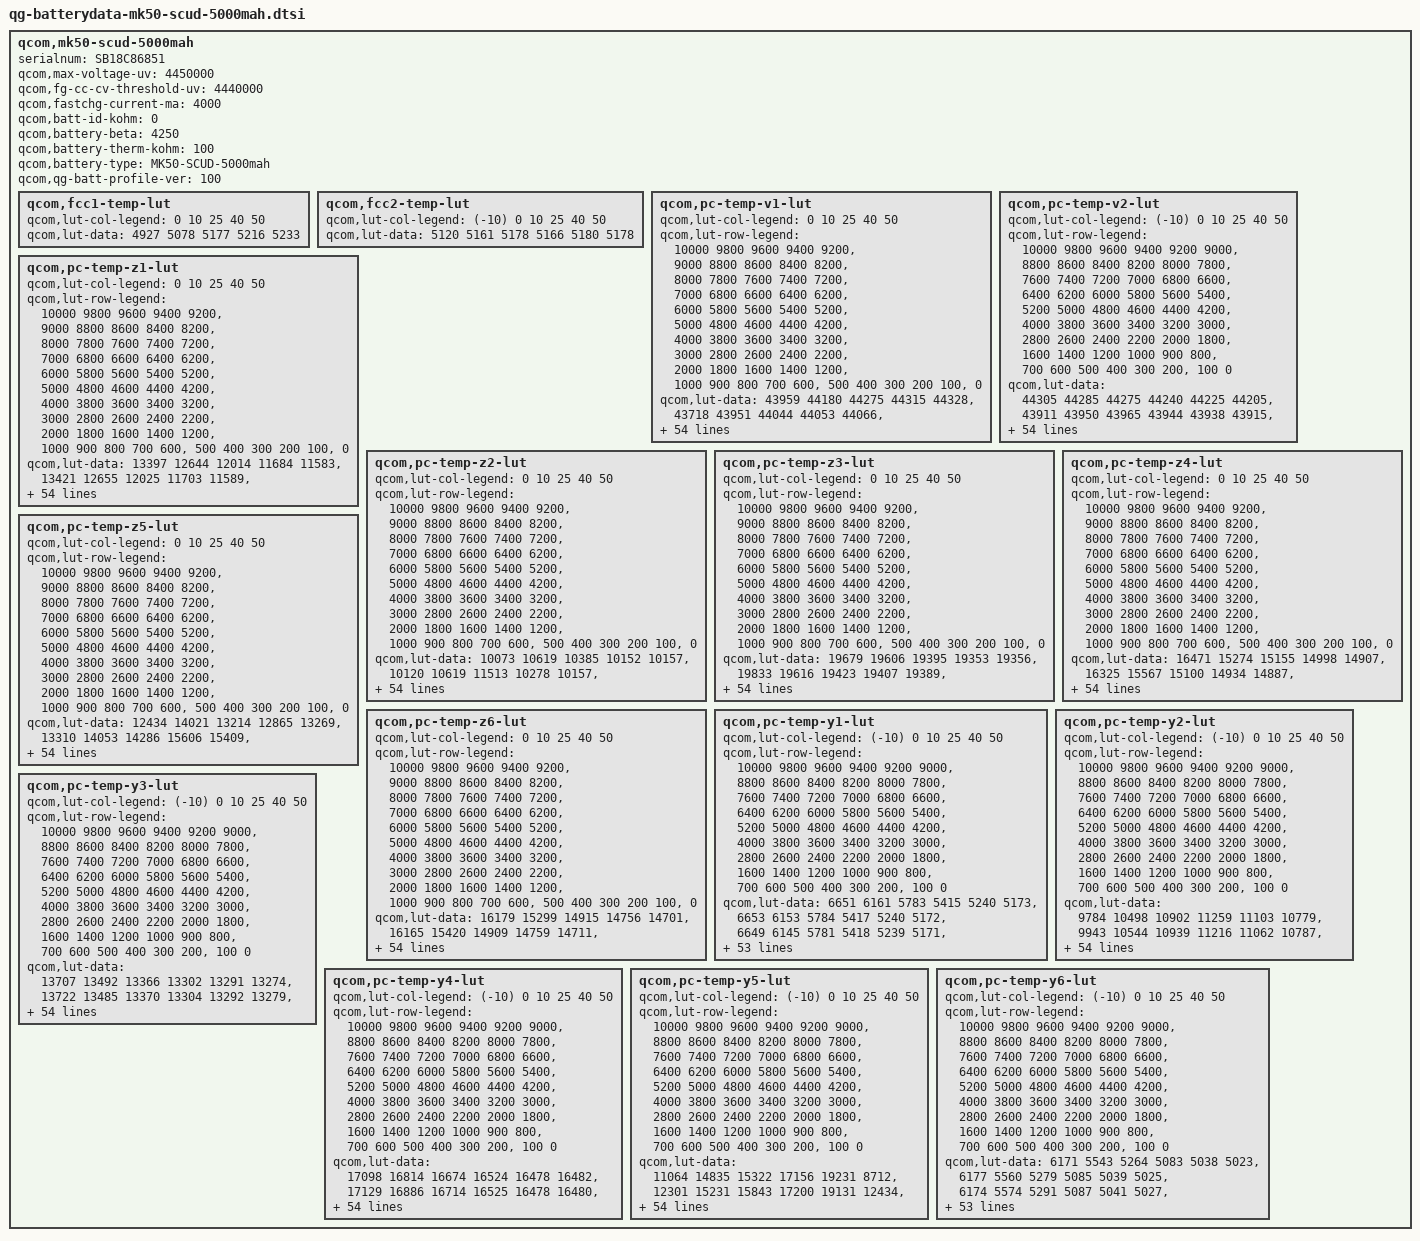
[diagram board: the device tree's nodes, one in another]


qcom,mk50-scud-5000mah {
    serialnum = "SB18C86851";

    qcom,max-voltage-uv = <4450000>;
    qcom,fg-cc-cv-threshold-uv = <4440000>;
    qcom,fastchg-current-ma = <4000>;
    qcom,batt-id-kohm = <0>;
    qcom,battery-beta = <4250>;
    qcom,battery-therm-kohm = <100>;
    qcom,battery-type = "MK50-SCUD-5000mah";
    qcom,qg-batt-profile-ver = <100>;

	qcom,fcc1-temp-lut {
		qcom,lut-col-legend = <0 10 25 40 50>;
		qcom,lut-data = <4927 5078 5177 5216 5233>;
	};

	qcom,fcc2-temp-lut {
		qcom,lut-col-legend = <(-10) 0 10 25 40 50>;
		qcom,lut-data = <5120 5161 5178 5166 5180 5178>;
	};

	qcom,pc-temp-v1-lut {
		qcom,lut-col-legend = <0 10 25 40 50>;
		qcom,lut-row-legend = <10000 9800 9600 9400 9200>,
			<9000 8800 8600 8400 8200>,
			<8000 7800 7600 7400 7200>,
			<7000 6800 6600 6400 6200>,
			<6000 5800 5600 5400 5200>,
			<5000 4800 4600 4400 4200>,
			<4000 3800 3600 3400 3200>,
			<3000 2800 2600 2400 2200>,
			<2000 1800 1600 1400 1200>,
			<1000 900 800 700 600>,
			<500 400 300 200 100>,
			<0>;
		qcom,lut-data = <43959 44180 44275 44315 44328>,
			<43718 43951 44044 44053 44066>,
			<43478 43724 43830 43832 43841>,
			<43240 43494 43605 43627 43632>,
			<43002 43258 43375 43414 43417>,
			<42763 43016 43141 43187 43194>,
			<42523 42773 42901 42946 42961>,
			<42284 42531 42658 42703 42723>,
			<42051 42289 42412 42461 42483>,
			<41822 42050 42167 42219 42241>,
			<41596 41815 41927 41979 42003>,
			<41377 41584 41691 41741 41765>,
			<41162 41360 41462 41509 41531>,
			<40955 41143 41238 41278 41301>,
			<40749 40933 41020 41055 41078>,
			<40539 40727 40810 40843 40861>,
			<40327 40520 40603 40639 40650>,
			<40131 40314 40400 40439 40448>,
			<39956 40120 40203 40246 40254>,
			<39796 39948 40022 40061 40068>,
			<39644 39786 39865 39893 39903>,
			<39502 39620 39688 39717 39734>,
			<39363 39449 39426 39472 39503>,
			<39220 39257 39133 39173 39207>,
			<39075 39010 38942 38968 38993>,
			<38929 38772 38810 38843 38865>,
			<38775 38644 38704 38739 38761>,
			<38642 38565 38616 38641 38660>,
			<38545 38499 38540 38551 38567>,
			<38467 38439 38466 38465 38477>,
			<38407 38386 38398 38386 38392>,
			<38360 38337 38334 38312 38312>,
			<38321 38292 38276 38245 38234>,
			<38285 38249 38220 38181 38160>,
			<38254 38210 38167 38116 38087>,
			<38222 38171 38117 38051 38017>,
			<38190 38134 38069 37991 37951>,
			<38154 38095 38024 37941 37895>,
			<38099 38041 37968 37880 37829>,
			<38018 37956 37881 37789 37729>,
			<37919 37850 37771 37674 37605>,
			<37790 37729 37653 37556 37482>,
			<37648 37588 37518 37428 37355>,
			<37506 37420 37355 37274 37204>,
			<37346 37262 37196 37124 37060>,
			<37223 37158 37088 37027 36971>,
			<37178 37129 37057 36992 36938>,
			<37142 37097 37038 36972 36914>,
			<37109 37070 37016 36952 36894>,
			<37068 37032 36977 36908 36842>,
			<36912 36861 36790 36696 36610>,
			<36482 36432 36371 36263 36172>,
			<35900 35841 35793 35684 35592>,
			<35093 35023 35004 34897 34803>,
			<33747 33682 33778 33686 33586>,
			<30000 30000 30000 30000 30000>;
	};

	qcom,pc-temp-v2-lut {
		qcom,lut-col-legend = <(-10) 0 10 25 40 50>;
		qcom,lut-row-legend = <10000 9800 9600 9400 9200 9000>,
			<8800 8600 8400 8200 8000 7800>,
			<7600 7400 7200 7000 6800 6600>,
			<6400 6200 6000 5800 5600 5400>,
			<5200 5000 4800 4600 4400 4200>,
			<4000 3800 3600 3400 3200 3000>,
			<2800 2600 2400 2200 2000 1800>,
			<1600 1400 1200 1000 900 800>,
			<700 600 500 400 300 200>,
			<100 0>;
		qcom,lut-data = <44305 44285 44275 44240 44225 44205>,
			<43911 43950 43965 43944 43938 43915>,
			<43561 43644 43679 43670 43672 43648>,
			<43264 43373 43421 43421 43427 43406>,
			<43013 43132 43189 43197 43203 43187>,
			<42761 42891 42954 42968 42975 42962>,
			<42484 42643 42708 42728 42737 42722>,
			<42214 42395 42460 42485 42495 42479>,
			<41988 42145 42212 42242 42254 42240>,
			<41790 41894 41963 42000 42011 42001>,
			<41570 41636 41723 41762 41773 41766>,
			<41294 41352 41492 41526 41537 41530>,
			<41036 41102 41267 41297 41307 41299>,
			<40877 40933 41051 41079 41081 41074>,
			<40751 40792 40838 40866 40861 40853>,
			<40548 40615 40629 40652 40647 40639>,
			<40156 40398 40424 40435 40439 40431>,
			<39761 40150 40212 40229 40239 40231>,
			<39487 39840 39984 40048 40053 40046>,
			<39256 39524 39748 39869 39870 39865>,
			<39050 39300 39517 39659 39680 39680>,
			<38864 39125 39287 39420 39483 39490>,
			<38691 38952 39081 39193 39272 39283>,
			<38514 38771 38893 38981 39032 39042>,
			<38356 38595 38726 38796 38821 38827>,
			<38255 38413 38580 38650 38672 38677>,
			<38184 38234 38449 38528 38551 38555>,
			<38123 38115 38329 38416 38441 38443>,
			<38067 38041 38217 38314 38340 38340>,
			<38016 37985 38112 38220 38247 38245>,
			<37963 37940 38008 38134 38166 38160>,
			<37910 37901 37916 38056 38090 38082>,
			<37856 37859 37858 37985 38014 38008>,
			<37800 37816 37816 37919 37940 37940>,
			<37742 37771 37778 37854 37865 37864>,
			<37681 37724 37742 37788 37790 37774>,
			<37616 37673 37704 37721 37711 37679>,
			<37546 37613 37658 37653 37621 37578>,
			<37464 37541 37601 37582 37524 37475>,
			<37379 37461 37530 37503 37430 37378>,
			<37295 37368 37434 37412 37340 37287>,
			<37210 37263 37316 37311 37244 37192>,
			<37123 37136 37167 37188 37126 37077>,
			<37041 36998 37006 37044 36984 36929>,
			<36960 36862 36864 36914 36873 36823>,
			<36865 36755 36765 36851 36823 36776>,
			<36814 36719 36729 36835 36812 36765>,
			<36764 36686 36690 36818 36802 36750>,
			<36705 36649 36640 36791 36776 36724>,
			<36634 36587 36557 36735 36709 36647>,
			<36516 36424 36357 36514 36435 36343>,
			<36284 36043 35925 36050 35946 35848>,
			<35841 35411 35303 35423 35297 35193>,
			<35110 34464 34428 34570 34389 34281>,
			<34094 32977 33019 33271 33036 32915>,
			<32450 29101 27865 28317 28185 28210>;
	};

	qcom,pc-temp-z1-lut {
		qcom,lut-col-legend = <0 10 25 40 50>;
		qcom,lut-row-legend = <10000 9800 9600 9400 9200>,
			<9000 8800 8600 8400 8200>,
			<8000 7800 7600 7400 7200>,
			<7000 6800 6600 6400 6200>,
			<6000 5800 5600 5400 5200>,
			<5000 4800 4600 4400 4200>,
			<4000 3800 3600 3400 3200>,
			<3000 2800 2600 2400 2200>,
			<2000 1800 1600 1400 1200>,
			<1000 900 800 700 600>,
			<500 400 300 200 100>,
			<0>;
		qcom,lut-data = <13397 12644 12014 11684 11583>,
			<13421 12655 12025 11703 11589>,
			<13420 12663 12020 11701 11586>,
			<13406 12661 12019 11696 11582>,
			<13397 12667 12014 11694 11581>,
			<13405 12674 12007 11690 11580>,
			<13415 12671 12000 11684 11577>,
			<13414 12654 11995 11680 11575>,
			<13417 12635 11989 11676 11574>,
			<13428 12623 11983 11674 11573>,
			<13417 12611 11977 11675 11574>,
			<13370 12601 11974 11676 11577>,
			<13338 12594 11974 11677 11578>,
			<13335 12588 11975 11677 11578>,
			<13336 12581 11976 11677 11578>,
			<13322 12573 11976 11677 11578>,
			<13293 12572 11975 11677 11579>,
			<13271 12576 11973 11677 11580>,
			<13256 12577 11970 11677 11580>,
			<13244 12572 11970 11678 11581>,
			<13236 12565 11972 11678 11582>,
			<13233 12565 11974 11679 11582>,
			<13232 12573 11974 11678 11582>,
			<13229 12582 11974 11678 11582>,
			<13223 12584 11976 11678 11582>,
			<13222 12582 11980 11680 11583>,
			<13231 12582 11982 11682 11585>,
			<13240 12585 11984 11684 11586>,
			<13248 12588 11987 11687 11588>,
			<13264 12592 11990 11690 11590>,
			<13271 12598 11994 11693 11594>,
			<13261 12605 11998 11696 11597>,
			<13252 12612 12001 11700 11600>,
			<13254 12616 12005 11704 11603>,
			<13266 12617 12011 11708 11608>,
			<13275 12616 12019 11714 11613>,
			<13276 12620 12024 11718 11617>,
			<13277 12627 12027 11722 11621>,
			<13284 12636 12030 11725 11623>,
			<13299 12647 12035 11728 11625>,
			<13314 12659 12040 11732 11627>,
			<13325 12673 12047 11735 11629>,
			<13337 12685 12054 11738 11631>,
			<13356 12687 12059 11741 11634>,
			<13360 12690 12066 11746 11637>,
			<13358 12692 12075 11749 11639>,
			<13346 12711 12073 11748 11639>,
			<13379 12693 12075 11748 11639>,
			<13354 12705 12074 11750 11640>,
			<13364 12702 12079 11756 11644>,
			<13362 12707 12090 11761 11648>,
			<13399 12738 12099 11766 11653>,
			<13395 12737 12109 11777 11662>,
			<13399 12776 12129 11792 11677>,
			<13399 12776 12129 11792 11677>,
			<13399 12776 12129 11792 11677>;
	};

	qcom,pc-temp-z2-lut {
		qcom,lut-col-legend = <0 10 25 40 50>;
		qcom,lut-row-legend = <10000 9800 9600 9400 9200>,
			<9000 8800 8600 8400 8200>,
			<8000 7800 7600 7400 7200>,
			<7000 6800 6600 6400 6200>,
			<6000 5800 5600 5400 5200>,
			<5000 4800 4600 4400 4200>,
			<4000 3800 3600 3400 3200>,
			<3000 2800 2600 2400 2200>,
			<2000 1800 1600 1400 1200>,
			<1000 900 800 700 600>,
			<500 400 300 200 100>,
			<0>;
		qcom,lut-data = <10073 10619 10385 10152 10157>,
			<10120 10619 11513 10278 10157>,
			<10136 10419 11512 10434 10291>,
			<10129 10288 10806 10710 10314>,
			<10124 10258 10410 10949 10314>,
			<10129 10237 10366 10802 10306>,
			<10142 10222 10335 10416 10269>,
			<10150 10211 10313 10266 10231>,
			<10147 10202 10299 10232 10206>,
			<10139 10196 10288 10210 10184>,
			<10129 10192 10276 10204 10172>,
			<10117 10191 10267 10202 10171>,
			<10102 10191 10273 10202 10178>,
			<10085 10194 10295 10219 10190>,
			<10067 10200 10314 10252 10201>,
			<10061 10213 10327 10478 10208>,
			<10062 10232 10341 10758 10216>,
			<10065 10263 10360 10838 10232>,
			<10075 10289 10379 10874 10265>,
			<10087 10305 10387 10857 10284>,
			<10100 10320 10394 10580 10219>,
			<10115 10339 10406 10360 10129>,
			<10135 10364 10488 10428 10205>,
			<10165 10390 10600 10552 10485>,
			<10200 10425 10608 10574 10583>,
			<10226 10452 10551 10440 10372>,
			<10246 10455 10519 10331 10182>,
			<10263 10451 10521 10332 10185>,
			<10278 10449 10526 10346 10207>,
			<10290 10452 10533 10379 10220>,
			<10300 10457 10544 10458 10227>,
			<10308 10462 10549 10496 10240>,
			<10317 10469 10549 10496 10349>,
			<10328 10477 10548 10494 10472>,
			<10340 10485 10554 10495 10474>,
			<10354 10493 10566 10495 10436>,
			<10369 10502 10580 10499 10386>,
			<10386 10511 10596 10518 10301>,
			<10405 10524 10616 10546 10245>,
			<10427 10541 10644 10605 10372>,
			<10451 10560 10673 10670 10590>,
			<10484 10576 10688 10675 10626>,
			<10498 10594 10698 10662 10614>,
			<10353 10631 10710 10658 10598>,
			<10257 10820 10756 10659 10555>,
			<10187 11006 10870 10640 10398>,
			<10130 10980 10853 10544 10378>,
			<10081 11036 10844 10500 10355>,
			<10088 11019 10853 10511 10385>,
			<10033 11066 10919 10612 10501>,
			<9981 11077 10975 10592 10455>,
			<9932 10919 10995 10437 10186>,
			<9774 10756 10924 10302 10073>,
			<9696 10492 10808 10211 10023>,
			<9696 10492 10808 10211 10023>,
			<9696 10492 10808 10211 10023>;
	};

	qcom,pc-temp-z3-lut {
		qcom,lut-col-legend = <0 10 25 40 50>;
		qcom,lut-row-legend = <10000 9800 9600 9400 9200>,
			<9000 8800 8600 8400 8200>,
			<8000 7800 7600 7400 7200>,
			<7000 6800 6600 6400 6200>,
			<6000 5800 5600 5400 5200>,
			<5000 4800 4600 4400 4200>,
			<4000 3800 3600 3400 3200>,
			<3000 2800 2600 2400 2200>,
			<2000 1800 1600 1400 1200>,
			<1000 900 800 700 600>,
			<500 400 300 200 100>,
			<0>;
		qcom,lut-data = <19679 19606 19395 19353 19356>,
			<19833 19616 19423 19407 19389>,
			<19905 19657 19461 19442 19415>,
			<19921 19682 19511 19465 19441>,
			<19923 19696 19537 19474 19451>,
			<19913 19705 19541 19478 19459>,
			<19897 19705 19543 19484 19467>,
			<19887 19696 19543 19488 19470>,
			<19881 19686 19542 19487 19470>,
			<19874 19680 19540 19484 19470>,
			<19868 19675 19537 19480 19467>,
			<19862 19670 19531 19471 19460>,
			<19860 19661 19521 19463 19453>,
			<19863 19653 19506 19457 19447>,
			<19872 19648 19495 19454 19440>,
			<19877 19643 19489 19456 19435>,
			<19878 19635 19485 19460 19429>,
			<19874 19622 19483 19458 19425>,
			<19867 19615 19483 19450 19420>,
			<19859 19610 19480 19440 19415>,
			<19857 19605 19472 19422 19402>,
			<19857 19605 19467 19409 19390>,
			<19857 19612 19482 19415 19393>,
			<19851 19622 19507 19431 19407>,
			<19843 19636 19508 19434 19412>,
			<19842 19650 19494 19418 19394>,
			<19846 19649 19481 19401 19374>,
			<19848 19639 19472 19394 19367>,
			<19844 19630 19466 19389 19363>,
			<19834 19623 19465 19389 19363>,
			<19823 19616 19465 19391 19365>,
			<19812 19610 19465 19394 19369>,
			<19800 19606 19470 19400 19387>,
			<19789 19603 19474 19407 19406>,
			<19777 19602 19475 19413 19407>,
			<19765 19600 19476 19420 19405>,
			<19753 19597 19475 19420 19401>,
			<19741 19592 19468 19409 19387>,
			<19732 19586 19461 19400 19376>,
			<19723 19581 19458 19400 19378>,
			<19712 19574 19455 19399 19382>,
			<19698 19566 19450 19398 19386>,
			<19667 19555 19443 19396 19390>,
			<19430 19542 19437 19394 19391>,
			<19345 19502 19425 19389 19387>,
			<19324 19406 19406 19369 19362>,
			<19323 19320 19403 19367 19356>,
			<19319 19309 19391 19359 19350>,
			<19316 19295 19390 19354 19340>,
			<19312 19288 19384 19337 19331>,
			<19311 19292 19378 19345 19343>,
			<19320 19303 19356 19381 19380>,
			<19332 19307 19355 19384 19384>,
			<19345 19317 19348 19382 19382>,
			<19345 19317 19348 19382 19382>,
			<19345 19317 19348 19382 19382>;
	};

	qcom,pc-temp-z4-lut {
		qcom,lut-col-legend = <0 10 25 40 50>;
		qcom,lut-row-legend = <10000 9800 9600 9400 9200>,
			<9000 8800 8600 8400 8200>,
			<8000 7800 7600 7400 7200>,
			<7000 6800 6600 6400 6200>,
			<6000 5800 5600 5400 5200>,
			<5000 4800 4600 4400 4200>,
			<4000 3800 3600 3400 3200>,
			<3000 2800 2600 2400 2200>,
			<2000 1800 1600 1400 1200>,
			<1000 900 800 700 600>,
			<500 400 300 200 100>,
			<0>;
		qcom,lut-data = <16471 15274 15155 14998 14907>,
			<16325 15567 15100 14934 14887>,
			<16155 15562 15181 14950 14893>,
			<15950 15445 15127 14955 14924>,
			<15761 15318 15045 14899 14889>,
			<15624 15200 14988 14872 14858>,
			<15513 15119 14942 14853 14834>,
			<15420 15060 14903 14833 14813>,
			<15342 15011 14868 14811 14793>,
			<15275 14968 14838 14790 14774>,
			<15217 14931 14813 14771 14758>,
			<15166 14903 14793 14754 14743>,
			<15118 14881 14779 14742 14733>,
			<15070 14861 14769 14735 14727>,
			<15028 14838 14761 14726 14722>,
			<15003 14821 14754 14704 14717>,
			<14989 14815 14748 14681 14711>,
			<14975 14812 14741 14676 14706>,
			<14954 14810 14734 14674 14700>,
			<14926 14798 14729 14674 14698>,
			<14895 14781 14725 14684 14699>,
			<14861 14772 14723 14701 14703>,
			<14834 14765 14753 14734 14725>,
			<14819 14764 14811 14801 14793>,
			<14809 14802 14842 14839 14836>,
			<14809 14856 14861 14855 14854>,
			<14825 14864 14867 14861 14863>,
			<14840 14859 14861 14857 14859>,
			<14845 14851 14848 14846 14847>,
			<14847 14841 14835 14832 14834>,
			<14848 14829 14818 14815 14818>,
			<14842 14817 14801 14796 14796>,
			<14833 14803 14781 14773 14762>,
			<14825 14791 14764 14751 14728>,
			<14816 14779 14750 14733 14715>,
			<14807 14768 14740 14718 14707>,
			<14797 14759 14735 14713 14705>,
			<14788 14750 14732 14712 14707>,
			<14776 14745 14731 14711 14709>,
			<14763 14743 14735 14719 14716>,
			<14755 14740 14741 14730 14726>,
			<14752 14734 14739 14731 14726>,
			<14756 14725 14732 14728 14717>,
			<14975 14715 14726 14727 14716>,
			<14962 14701 14711 14721 14714>,
			<14925 14738 14680 14694 14695>,
			<14924 14826 14674 14692 14696>,
			<14922 14830 14669 14684 14688>,
			<14918 14838 14654 14665 14671>,
			<14913 14837 14650 14665 14658>,
			<14906 14832 14668 14686 14682>,
			<14921 14838 14714 14676 14678>,
			<14925 14842 14718 14679 14681>,
			<14940 14849 14731 14685 14688>,
			<14940 14849 14731 14685 14688>,
			<14940 14849 14731 14685 14688>;
	};

	qcom,pc-temp-z5-lut {
		qcom,lut-col-legend = <0 10 25 40 50>;
		qcom,lut-row-legend = <10000 9800 9600 9400 9200>,
			<9000 8800 8600 8400 8200>,
			<8000 7800 7600 7400 7200>,
			<7000 6800 6600 6400 6200>,
			<6000 5800 5600 5400 5200>,
			<5000 4800 4600 4400 4200>,
			<4000 3800 3600 3400 3200>,
			<3000 2800 2600 2400 2200>,
			<2000 1800 1600 1400 1200>,
			<1000 900 800 700 600>,
			<500 400 300 200 100>,
			<0>;
		qcom,lut-data = <12434 14021 13214 12865 13269>,
			<13310 14053 14286 15606 15409>,
			<13848 14558 14634 17266 17440>,
			<14120 15102 15759 17189 17856>,
			<14284 15647 16715 17559 18691>,
			<14414 16164 17091 18130 19590>,
			<14567 16494 17379 18985 20410>,
			<14749 16677 17769 19705 21182>,
			<14945 16870 18310 20155 21918>,
			<15133 17274 18915 20543 22504>,
			<15304 17817 19583 20946 23000>,
			<15484 18240 20096 21453 23800>,
			<15748 18549 20212 21907 24344>,
			<16291 18932 20215 22490 24608>,
			<17070 19797 20293 23520 24924>,
			<17632 20806 20687 27416 25417>,
			<18015 21012 21271 31933 26340>,
			<18292 20791 21989 32971 27448>,
			<18580 20702 22839 33056 28849>,
			<19150 21243 23549 32599 29503>,
			<20216 22367 24069 28650 27479>,
			<22418 24259 25046 25358 24740>,
			<25314 29437 35187 28454 26141>,
			<28975 36087 50213 36202 31868>,
			<33647 44162 50497 37878 33759>,
			<38507 50847 38735 29724 26992>,
			<44095 49791 29744 22135 19896>,
			<47397 42413 26043 19915 17919>,
			<46875 36697 23845 18669 16846>,
			<45084 33866 23268 18458 16623>,
			<43098 32083 22997 18422 16576>,
			<40690 31731 23065 18439 16605>,
			<38378 31691 24472 19233 18881>,
			<36656 31886 26570 20787 22506>,
			<35114 33142 29466 23837 25047>,
			<33796 34627 32650 28269 27206>,
			<32510 35592 33446 29323 27591>,
			<31626 36396 33295 28285 25597>,
			<31957 36866 33117 27589 24021>,
			<33316 37308 32927 27838 25187>,
			<33970 37532 32542 28250 27183>,
			<32788 36447 31141 27374 27066>,
			<29796 34329 28596 24234 25367>,
			<15491 33705 28441 23975 25456>,
			<12745 31298 29296 24134 25458>,
			<12660 21904 31131 22565 20828>,
			<12582 13344 29457 21779 19003>,
			<12490 12852 25742 20755 18669>,
			<12410 12423 26736 21891 18557>,
			<12364 12315 26662 19180 18736>,
			<12445 12495 22960 18876 19453>,
			<12513 12691 16402 21356 21316>,
			<12519 12649 15700 20004 20060>,
			<12534 12705 14745 18071 17771>,
			<12534 12705 14745 18071 17771>,
			<12534 12705 14745 18071 17771>;
	};

	qcom,pc-temp-z6-lut {
		qcom,lut-col-legend = <0 10 25 40 50>;
		qcom,lut-row-legend = <10000 9800 9600 9400 9200>,
			<9000 8800 8600 8400 8200>,
			<8000 7800 7600 7400 7200>,
			<7000 6800 6600 6400 6200>,
			<6000 5800 5600 5400 5200>,
			<5000 4800 4600 4400 4200>,
			<4000 3800 3600 3400 3200>,
			<3000 2800 2600 2400 2200>,
			<2000 1800 1600 1400 1200>,
			<1000 900 800 700 600>,
			<500 400 300 200 100>,
			<0>;
		qcom,lut-data = <16179 15299 14915 14756 14701>,
			<16165 15420 14909 14759 14711>,
			<16126 15424 14958 14783 14727>,
			<16034 15376 14953 14796 14751>,
			<15927 15322 14936 14780 14744>,
			<15844 15269 14915 14771 14737>,
			<15776 15225 14891 14764 14731>,
			<15720 15188 14872 14757 14724>,
			<15675 15156 14855 14747 14717>,
			<15636 15129 14840 14737 14709>,
			<15599 15106 14826 14726 14700>,
			<15565 15087 14814 14715 14691>,
			<15536 15069 14802 14706 14683>,
			<15510 15054 14790 14699 14676>,
			<15490 15039 14780 14693 14670>,
			<15476 15026 14774 14685 14664>,
			<15464 15016 14768 14678 14658>,
			<15451 15008 14764 14672 14653>,
			<15432 15001 14760 14667 14648>,
			<15411 14991 14756 14663 14643>,
			<15393 14983 14749 14659 14637>,
			<15376 14981 14746 14656 14631>,
			<15363 14982 14769 14671 14642>,
			<15352 14985 14807 14711 14682>,
			<15343 15010 14816 14725 14698>,
			<15343 15042 14817 14723 14695>,
			<15353 15045 14817 14719 14691>,
			<15361 15039 14811 14714 14686>,
			<15361 15032 14803 14708 14680>,
			<15358 15025 14796 14702 14674>,
			<15354 15018 14790 14696 14668>,
			<15348 15011 14784 14691 14663>,
			<15340 15004 14779 14684 14658>,
			<15332 14998 14774 14679 14654>,
			<15323 14994 14770 14676 14650>,
			<15316 14990 14767 14674 14647>,
			<15310 14986 14764 14670 14642>,
			<15305 14982 14759 14664 14635>,
			<15302 14980 14757 14660 14631>,
			<15300 14980 14758 14663 14635>,
			<15298 14980 14760 14667 14641>,
			<15296 14978 14758 14667 14642>,
			<15293 14973 14753 14665 14640>,
			<15277 14967 14749 14664 14640>,
			<15235 14946 14739 14659 14638>,
			<15212 14920 14718 14638 14617>,
			<15212 14914 14714 14635 14614>,
			<15210 14910 14706 14628 14607>,
			<15208 14907 14699 14617 14595>,
			<15210 14907 14695 14609 14584>,
			<15213 14913 14703 14622 14600>,
			<15235 14929 14714 14639 14621>,
			<15255 14942 14721 14645 14628>,
			<15286 14965 14729 14650 14634>,
			<15286 14965 14729 14650 14634>,
			<15286 14965 14729 14650 14634>;
	};

	qcom,pc-temp-y1-lut {
		qcom,lut-col-legend = <(-10) 0 10 25 40 50>;
		qcom,lut-row-legend = <10000 9800 9600 9400 9200 9000>,
			<8800 8600 8400 8200 8000 7800>,
			<7600 7400 7200 7000 6800 6600>,
			<6400 6200 6000 5800 5600 5400>,
			<5200 5000 4800 4600 4400 4200>,
			<4000 3800 3600 3400 3200 3000>,
			<2800 2600 2400 2200 2000 1800>,
			<1600 1400 1200 1000 900 800>,
			<700 600 500 400 300 200>,
			<100 0>;
		qcom,lut-data = <6651 6161 5783 5415 5240 5173>,
			<6653 6153 5784 5417 5240 5172>,
			<6649 6145 5781 5418 5239 5171>,
			<6643 6139 5777 5418 5238 5171>,
			<6638 6135 5773 5418 5236 5170>,
			<6639 6133 5771 5418 5235 5170>,
			<6643 6133 5770 5416 5233 5170>,
			<6647 6134 5768 5413 5231 5170>,
			<6642 6135 5768 5411 5230 5169>,
			<6630 6141 5767 5408 5229 5167>,
			<6626 6144 5767 5407 5228 5166>,
			<6631 6138 5767 5407 5228 5166>,
			<6637 6133 5768 5407 5228 5166>,
			<6637 6137 5768 5406 5227 5166>,
			<6635 6144 5768 5405 5227 5166>,
			<6636 6148 5767 5406 5227 5166>,
			<6648 6152 5767 5408 5227 5167>,
			<6660 6154 5768 5409 5228 5168>,
			<6667 6154 5769 5410 5229 5168>,
			<6673 6155 5770 5410 5230 5168>,
			<6673 6154 5773 5410 5230 5169>,
			<6672 6146 5775 5412 5231 5169>,
			<6670 6142 5774 5415 5231 5170>,
			<6661 6142 5772 5417 5232 5171>,
			<6646 6142 5771 5420 5234 5172>,
			<6634 6147 5775 5422 5236 5173>,
			<6623 6158 5781 5425 5237 5175>,
			<6617 6159 5785 5426 5239 5176>,
			<6613 6146 5787 5428 5242 5177>,
			<6610 6137 5786 5431 5245 5179>,
			<6608 6140 5789 5434 5247 5182>,
			<6606 6144 5796 5436 5249 5184>,
			<6609 6143 5794 5438 5251 5187>,
			<6621 6142 5784 5441 5253 5189>,
			<6634 6140 5780 5444 5255 5190>,
			<6642 6132 5780 5447 5258 5190>,
			<6644 6127 5780 5450 5259 5191>,
			<6634 6129 5781 5450 5260 5192>,
			<6609 6131 5785 5450 5260 5193>,
			<6589 6133 5788 5450 5260 5193>,
			<6582 6138 5789 5450 5261 5194>,
			<6587 6143 5786 5450 5262 5195>,
			<6600 6147 5780 5457 5263 5196>,
			<6591 6128 5791 5460 5266 5199>,
			<6668 6158 5800 5463 5269 5203>,
			<6646 6145 5799 5469 5272 5204>,
			<6643 6146 5800 5473 5272 5204>,
			<6620 6135 5794 5475 5272 5203>,
			<6615 6153 5802 5472 5272 5204>,
			<6616 6154 5799 5473 5273 5204>,
			<6617 6157 5807 5478 5274 5206>,
			<6644 6156 5804 5485 5278 5211>,
			<6753 6175 5819 5495 5286 5219>,
			<6906 6295 5845 5513 5297 5229>,
			<6906 6295 5845 5513 5297 5229>,
			<6906 6295 5845 5513 5297 5229>;
	};

	qcom,pc-temp-y2-lut {
		qcom,lut-col-legend = <(-10) 0 10 25 40 50>;
		qcom,lut-row-legend = <10000 9800 9600 9400 9200 9000>,
			<8800 8600 8400 8200 8000 7800>,
			<7600 7400 7200 7000 6800 6600>,
			<6400 6200 6000 5800 5600 5400>,
			<5200 5000 4800 4600 4400 4200>,
			<4000 3800 3600 3400 3200 3000>,
			<2800 2600 2400 2200 2000 1800>,
			<1600 1400 1200 1000 900 800>,
			<700 600 500 400 300 200>,
			<100 0>;
		qcom,lut-data = <9784 10498 10902 11259 11103 10779>,
			<9943 10544 10939 11216 11062 10787>,
			<10071 10590 10960 11175 11022 10785>,
			<10166 10633 10969 11137 10985 10775>,
			<10224 10670 10969 11101 10951 10761>,
			<10240 10698 10966 11070 10921 10742>,
			<10195 10724 10951 11039 10891 10711>,
			<10141 10740 10930 11016 10868 10685>,
			<10197 10670 10912 11005 10856 10678>,
			<10404 10482 10893 10997 10846 10674>,
			<10560 10429 10868 10992 10839 10673>,
			<10662 10563 10822 10986 10831 10678>,
			<10720 10735 10792 10979 10828 10684>,
			<10691 10881 10816 10968 10837 10695>,
			<10621 11006 10879 10954 10854 10713>,
			<10613 11014 10976 10964 10870 10731>,
			<10727 10942 11146 11043 10891 10753>,
			<10816 10898 11232 11135 10924 10784>,
			<10469 10949 11226 11228 11009 10838>,
			<9847 11030 11217 11310 11128 10922>,
			<9697 11075 11224 11341 11236 11052>,
			<9691 11106 11249 11357 11340 11224>,
			<9687 11116 11274 11362 11361 11269>,
			<9683 11111 11295 11359 11296 11158>,
			<9680 11101 11312 11361 11243 11056>,
			<9677 11083 11329 11383 11267 11092>,
			<9674 11061 11345 11425 11324 11202>,
			<9672 11037 11349 11460 11370 11267>,
			<9670 10760 11344 11489 11407 11303>,
			<9669 10451 11341 11516 11444 11342>,
			<9668 10112 11361 11548 11491 11406>,
			<9666 9759 11384 11577 11543 11477>,
			<9666 9709 11376 11581 11588 11535>,
			<9665 9692 11334 11573 11632 11594>,
			<9664 9682 11285 11562 11638 11620>,
			<9664 9675 11234 11545 11608 11616>,
			<9664 9671 11175 11527 11565 11605>,
			<9664 9668 11110 11512 11520 11550>,
			<9664 9666 11038 11493 11467 11454>,
			<9663 9664 10958 11467 11427 11394>,
			<9663 9663 10872 11437 11399 11356>,
			<9663 9663 10730 11427 11387 11374>,
			<9663 9662 10190 11417 11386 11388>,
			<9663 9662 9851 11386 11322 11171>,
			<9662 9661 9765 11381 11156 10960>,
			<9662 9661 9699 11264 11052 10888>,
			<9661 9660 9682 11239 11094 10898>,
			<9661 9660 9674 11213 11093 10899>,
			<9661 9660 9669 11206 11119 10981>,
			<9660 9659 9666 11217 11137 10977>,
			<9659 9659 9662 11213 11081 10888>,
			<9656 9658 9660 11128 11004 10806>,
			<9653 9655 9659 11008 10889 10683>,
			<9651 9652 9657 10890 10747 10581>,
			<9651 9652 9657 10890 10747 10581>,
			<9651 9652 9657 10890 10747 10581>;
	};

	qcom,pc-temp-y3-lut {
		qcom,lut-col-legend = <(-10) 0 10 25 40 50>;
		qcom,lut-row-legend = <10000 9800 9600 9400 9200 9000>,
			<8800 8600 8400 8200 8000 7800>,
			<7600 7400 7200 7000 6800 6600>,
			<6400 6200 6000 5800 5600 5400>,
			<5200 5000 4800 4600 4400 4200>,
			<4000 3800 3600 3400 3200 3000>,
			<2800 2600 2400 2200 2000 1800>,
			<1600 1400 1200 1000 900 800>,
			<700 600 500 400 300 200>,
			<100 0>;
		qcom,lut-data = <13707 13492 13366 13302 13291 13274>,
			<13722 13485 13370 13304 13292 13279>,
			<13727 13481 13374 13307 13293 13283>,
			<13725 13479 13378 13309 13294 13288>,
			<13719 13478 13382 13311 13295 13290>,
			<13709 13478 13384 13312 13296 13291>,
			<13688 13482 13385 13312 13297 13290>,
			<13668 13485 13386 13313 13298 13289>,
			<13674 13481 13387 13313 13299 13290>,
			<13699 13470 13388 13313 13299 13294>,
			<13702 13467 13389 13313 13300 13296>,
			<13583 13471 13389 13314 13301 13297>,
			<13467 13474 13389 13315 13302 13298>,
			<13471 13453 13389 13318 13302 13299>,
			<13492 13413 13390 13322 13303 13299>,
			<13500 13405 13387 13322 13304 13300>,
			<13501 13415 13374 13320 13307 13300>,
			<13501 13421 13365 13318 13309 13300>,
			<13492 13415 13364 13318 13307 13301>,
			<13475 13404 13363 13318 13305 13302>,
			<13471 13398 13359 13317 13305 13302>,
			<13471 13393 13352 13315 13304 13301>,
			<13471 13388 13346 13312 13303 13299>,
			<13461 13380 13343 13306 13296 13292>,
			<13447 13373 13340 13302 13291 13287>,
			<13447 13364 13337 13301 13290 13287>,
			<13460 13353 13335 13300 13290 13288>,
			<13479 13345 13333 13300 13289 13288>,
			<13509 13337 13331 13299 13287 13286>,
			<13546 13334 13329 13299 13286 13284>,
			<13583 13342 13323 13299 13287 13284>,
			<13623 13361 13318 13299 13288 13284>,
			<13667 13381 13318 13299 13288 13285>,
			<13716 13404 13321 13299 13288 13286>,
			<13765 13433 13325 13299 13288 13287>,
			<13809 13471 13330 13300 13288 13287>,
			<13852 13519 13337 13300 13288 13286>,
			<13894 13574 13343 13300 13288 13286>,
			<13932 13636 13349 13301 13288 13287>,
			<13966 13702 13353 13301 13288 13287>,
			<13998 13771 13356 13301 13289 13288>,
			<14030 13835 13359 13302 13290 13289>,
			<14063 13888 13364 13302 13289 13288>,
			<14100 13921 13368 13300 13285 13284>,
			<14109 13912 13372 13296 13284 13284>,
			<14187 14040 13417 13301 13290 13293>,
			<14247 14105 13453 13306 13297 13296>,
			<14316 14160 13505 13310 13303 13299>,
			<14415 14221 13580 13315 13304 13302>,
			<14569 14302 13681 13320 13304 13301>,
			<14831 14427 13839 13316 13297 13295>,
			<15752 14724 14047 13315 13298 13294>,
			<19249 16086 14343 13323 13301 13298>,
			<34040 23599 14881 13335 13308 13308>,
			<34040 23599 14881 13335 13308 13308>,
			<34040 23599 14881 13335 13308 13308>;
	};

	qcom,pc-temp-y4-lut {
		qcom,lut-col-legend = <(-10) 0 10 25 40 50>;
		qcom,lut-row-legend = <10000 9800 9600 9400 9200 9000>,
			<8800 8600 8400 8200 8000 7800>,
			<7600 7400 7200 7000 6800 6600>,
			<6400 6200 6000 5800 5600 5400>,
			<5200 5000 4800 4600 4400 4200>,
			<4000 3800 3600 3400 3200 3000>,
			<2800 2600 2400 2200 2000 1800>,
			<1600 1400 1200 1000 900 800>,
			<700 600 500 400 300 200>,
			<100 0>;
		qcom,lut-data = <17098 16814 16674 16524 16478 16482>,
			<17129 16886 16714 16525 16478 16480>,
			<17193 16968 16754 16526 16479 16478>,
			<17264 17044 16788 16528 16480 16478>,
			<17322 17097 16811 16529 16480 16478>,
			<17344 17113 16818 16531 16481 16478>,
			<17344 17097 16810 16532 16482 16481>,
			<17344 17078 16797 16534 16483 16484>,
			<17314 17080 16787 16536 16485 16484>,
			<17226 17088 16776 16540 16488 16484>,
			<17201 17089 16771 16545 16491 16484>,
			<17383 17073 16769 16552 16495 16487>,
			<17561 17060 16768 16558 16500 16491>,
			<17561 17146 16791 16564 16507 16495>,
			<17529 17306 16839 16569 16514 16500>,
			<17452 17329 16875 16580 16521 16506>,
			<17158 17239 16906 16606 16528 16514>,
			<16940 17124 16917 16632 16537 16523>,
			<16943 16980 16872 16657 16560 16537>,
			<16958 16850 16796 16676 16584 16551>,
			<16954 16816 16743 16667 16592 16562>,
			<16904 16805 16699 16621 16592 16573>,
			<16852 16789 16665 16578 16579 16570>,
			<16817 16754 16638 16540 16526 16523>,
			<16792 16709 16618 16516 16487 16483>,
			<16790 16653 16605 16514 16485 16480>,
			<16794 16594 16595 16513 16486 16479>,
			<16795 16581 16584 16515 16489 16481>,
			<16794 16604 16572 16519 16500 16492>,
			<16794 16634 16558 16524 16513 16505>,
			<16796 16656 16539 16531 16524 16517>,
			<16800 16676 16522 16537 16534 16528>,
			<16805 16693 16522 16542 16539 16537>,
			<16809 16711 16529 16546 16542 16543>,
			<16813 16728 16540 16547 16543 16545>,
			<16813 16740 16556 16541 16541 16540>,
			<16812 16750 16577 16531 16536 16531>,
			<16810 16760 16601 16526 16523 16518>,
			<16810 16768 16629 16522 16506 16505>,
			<16809 16771 16647 16520 16502 16502>,
			<16806 16770 16657 16519 16504 16507>,
			<16803 16765 16663 16521 16508 16512>,
			<16810 16751 16678 16521 16504 16509>,
			<16814 16723 16670 16502 16477 16476>,
			<16790 16696 16648 16481 16463 16459>,
			<16790 16704 16670 16495 16479 16480>,
			<16800 16712 16690 16511 16499 16513>,
			<16810 16728 16717 16532 16533 16551>,
			<16827 16754 16754 16565 16571 16591>,
			<16847 16788 16813 16600 16595 16601>,
			<16862 16804 16835 16569 16524 16517>,
			<16967 16778 16826 16536 16489 16495>,
			<17575 16951 16831 16549 16492 16496>,
			<23306 20495 16890 16588 16502 16499>,
			<23306 20495 16890 16588 16502 16499>,
			<23306 20495 16890 16588 16502 16499>;
	};

	qcom,pc-temp-y5-lut {
		qcom,lut-col-legend = <(-10) 0 10 25 40 50>;
		qcom,lut-row-legend = <10000 9800 9600 9400 9200 9000>,
			<8800 8600 8400 8200 8000 7800>,
			<7600 7400 7200 7000 6800 6600>,
			<6400 6200 6000 5800 5600 5400>,
			<5200 5000 4800 4600 4400 4200>,
			<4000 3800 3600 3400 3200 3000>,
			<2800 2600 2400 2200 2000 1800>,
			<1600 1400 1200 1000 900 800>,
			<700 600 500 400 300 200>,
			<100 0>;
		qcom,lut-data = <11064 14835 15322 17156 19231 8712>,
			<12301 15231 15843 17200 19131 12434>,
			<13961 15649 16394 17155 18859 15608>,
			<15625 16081 16919 17040 18505 17540>,
			<16875 16517 17361 16872 18160 18479>,
			<17296 16953 17666 16662 17907 18635>,
			<17065 17513 17907 16319 17605 17104>,
			<16786 17918 18050 15909 17271 15470>,
			<17933 17766 17906 15531 16965 15721>,
			<21541 17148 17549 15145 16605 16602>,
			<22747 16356 17483 14792 16256 16860>,
			<18397 15023 17816 14416 15936 16627>,
			<14152 14130 18067 14207 15603 16304>,
			<15552 14429 17089 14307 15140 15993>,
			<19631 15338 15447 14503 14702 15638>,
			<22023 16989 15300 14463 14659 15211>,
			<23315 20610 16312 13992 14795 14662>,
			<23911 22612 17780 13710 14864 14407>,
			<21082 21616 20630 14637 14637 14402>,
			<16061 20253 23201 16436 14418 14413>,
			<14950 20524 23228 18392 15683 15267>,
			<15068 22015 22602 20649 19242 17866>,
			<15127 22838 22361 21330 20566 19074>,
			<14130 23157 22503 20301 20056 19077>,
			<12650 23348 22734 19267 19308 18940>,
			<12265 22574 23036 19121 18760 18797>,
			<12160 19780 23413 19103 18206 18542>,
			<12149 17335 23802 19064 17494 18026>,
			<12280 14566 24322 19111 16513 16428>,
			<12470 13012 24548 19314 16077 15344>,
			<12596 12819 22197 19743 16426 15283>,
			<12708 12894 19025 20335 17112 15302>,
			<12844 13033 18588 21079 17637 15693>,
			<13029 13160 18777 22141 18109 17035>,
			<13189 13328 19030 22876 18593 18279>,
			<13364 13709 19610 23250 19706 19201>,
			<13633 14091 20099 23455 20903 19852>,
			<13758 14210 20026 23317 21055 20114>,
			<13617 14259 19736 22778 20666 20279>,
			<13434 14290 19379 22004 20382 20399>,
			<13364 14318 18781 20990 20194 20407>,
			<13279 14392 17898 20687 20050 20675>,
			<12985 14311 15776 20377 20895 21993>,
			<12885 14167 14173 20698 20309 20558>,
			<12992 13718 14142 20188 18214 18676>,
			<13075 13436 14132 18979 16745 17700>,
			<13086 13613 14055 18649 17759 16922>,
			<13321 13681 14001 18248 18158 16207>,
			<13464 13808 14019 18169 17471 16170>,
			<13847 14040 14005 18742 17272 16014>,
			<14052 14030 14413 18555 16847 16133>,
			<13066 13896 14096 19692 18391 16351>,
			<10715 12222 13832 20908 18228 16114>,
			<9185 9567 13182 21622 20103 19742>,
			<9185 9567 13182 21622 20103 19742>,
			<9185 9567 13182 21622 20103 19742>;
	};

	qcom,pc-temp-y6-lut {
		qcom,lut-col-legend = <(-10) 0 10 25 40 50>;
		qcom,lut-row-legend = <10000 9800 9600 9400 9200 9000>,
			<8800 8600 8400 8200 8000 7800>,
			<7600 7400 7200 7000 6800 6600>,
			<6400 6200 6000 5800 5600 5400>,
			<5200 5000 4800 4600 4400 4200>,
			<4000 3800 3600 3400 3200 3000>,
			<2800 2600 2400 2200 2000 1800>,
			<1600 1400 1200 1000 900 800>,
			<700 600 500 400 300 200>,
			<100 0>;
		qcom,lut-data = <6171 5543 5264 5083 5038 5023>,
			<6177 5560 5279 5085 5039 5025>,
			<6174 5574 5291 5087 5041 5027>,
			<6163 5584 5299 5089 5042 5030>,
			<6147 5590 5304 5090 5043 5032>,
			<6128 5591 5306 5091 5044 5033>,
			<6097 5588 5302 5091 5045 5033>,
			<6067 5582 5297 5092 5045 5034>,
			<6051 5575 5293 5093 5047 5035>,
			<6041 5567 5289 5094 5048 5037>,
			<6027 5561 5287 5095 5050 5039>,
			<5999 5554 5285 5097 5051 5040>,
			<5977 5551 5284 5099 5053 5042>,
			<5980 5562 5291 5102 5055 5044>,
			<5990 5584 5304 5106 5058 5046>,
			<5987 5587 5307 5111 5061 5048>,
			<5926 5572 5307 5116 5064 5050>,
			<5863 5550 5307 5122 5069 5053>,
			<5836 5509 5295 5128 5074 5057>,
			<5817 5467 5273 5134 5079 5062>,
			<5807 5458 5255 5131 5081 5065>,
			<5801 5456 5238 5116 5080 5066>,
			<5795 5453 5225 5101 5074 5064>,
			<5788 5444 5217 5086 5054 5045>,
			<5781 5433 5210 5077 5039 5030>,
			<5785 5420 5207 5076 5038 5029>,
			<5805 5406 5204 5076 5039 5030>,
			<5830 5403 5202 5076 5039 5030>,
			<5857 5412 5199 5078 5041 5032>,
			<5888 5429 5196 5080 5044 5035>,
			<5920 5453 5191 5082 5048 5038>,
			<5955 5486 5185 5084 5052 5041>,
			<5992 5525 5187 5086 5054 5044>,
			<6030 5571 5195 5088 5055 5048>,
			<6068 5621 5207 5089 5055 5048>,
			<6101 5674 5222 5088 5054 5047>,
			<6132 5730 5242 5086 5053 5044>,
			<6161 5787 5266 5086 5050 5041>,
			<6188 5845 5296 5086 5045 5037>,
			<6213 5901 5326 5085 5044 5036>,
			<6235 5954 5356 5086 5045 5039>,
			<6259 6002 5386 5087 5047 5041>,
			<6288 6041 5415 5089 5046 5040>,
			<6321 6060 5421 5083 5035 5027>,
			<6333 6053 5423 5075 5031 5023>,
			<6396 6149 5504 5086 5041 5036>,
			<6444 6199 5562 5094 5052 5048>,
			<6499 6247 5632 5104 5065 5061>,
			<6578 6303 5720 5118 5077 5074>,
			<6703 6371 5829 5131 5084 5077>,
			<6907 6472 5964 5119 5058 5048>,
			<7650 6685 6125 5112 5050 5043>,
			<10386 7742 6353 5127 5054 5047>,
			<22075 14041 6774 5156 5064 5057>,
			<22075 14041 6774 5156 5064 5057>,
			<22075 14041 6774 5156 5064 5057>;
	};

};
